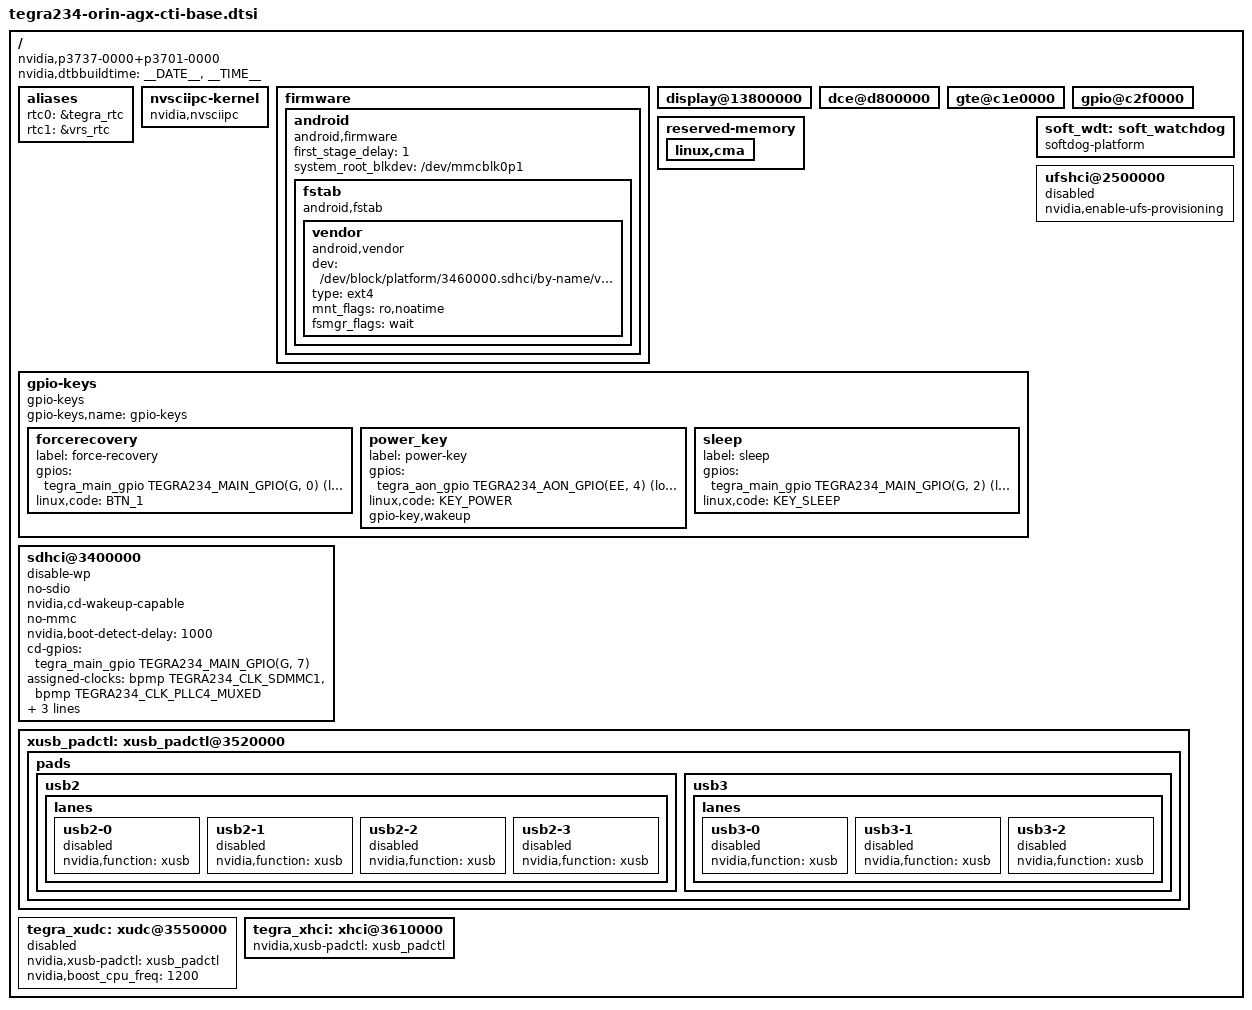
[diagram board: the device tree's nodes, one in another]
/*
 * Top level DTS file for CVM:P3701-0000 and CVB:P3737-0000.
 *
 * Copyright (c) 2021-2022, NVIDIA CORPORATION.  All rights reserved.
 *
 * This program is free software; you can redistribute it and/or modify
 * it under the terms of the GNU General Public License as published by
 * the Free Software Foundation; version 2 of the License.
 *
 * This program is distributed in the hope that it will be useful, but WITHOUT
 * ANY WARRANTY; without even the implied warranty of MERCHANTABILITY or
 * FITNESS FOR A PARTICULAR PURPOSE.  See the GNU General Public License for
 * more details.
 */

/dts-v1/;
#include <dt-bindings/gpio/tegra234-gpio.h>
#include <dt-bindings/input/input.h>
#include <tegra234-soc/mods-simple-bus.dtsi>

#include "../cvm/tegra234-p3701-0000.dtsi"
#include "../tegra234-dcb-p3701-0000-a02-p3737-0000-a01.dtsi"
#include "../tegra234-p3701-0000-prod.dtsi"

#include "cti_common/tegra234-orin-agx-cti-ethernet.dtsi"
#include "cti_common/tegra234-orin-agx-cti-thermal.dtsi"
#include "cti_common/tegra234-orin-agx-cti-cpu.dtsi"
#include "cti_common/tegra234-orin-agx-cti-power-tree.dtsi"

/ {
	nvidia,dtbbuildtime = __DATE__, __TIME__;

	compatible = "nvidia,p3737-0000+p3701-0000", "nvidia,tegra234", "nvidia,tegra23x";
    aliases {
        rtc0 = &tegra_rtc;
        rtc1 = &vrs_rtc;
    };

	nvsciipc-kernel {
		compatible = "nvidia,nvsciipc";
		status = "okay";
	};

	firmware {
		android {
			compatible = "android,firmware";
			first_stage_delay = "1";
			system_root_blkdev = "/dev/mmcblk0p1";
			fstab {
				compatible = "android,fstab";
				vendor {
					compatible = "android,vendor";
					dev = "/dev/block/platform/3460000.sdhci/by-name/vendor";
					type = "ext4";
					mnt_flags = "ro,noatime";
					fsmgr_flags = "wait";
				};
			};
		};
	};
	
	display@13800000 {
		status = "okay";
	};
	dce@d800000 {
		status = "okay";
	};
	gte@c1e0000 {
		status = "okay";
	};
	gpio@c2f0000 {
		/delete-property/ use-timestamp;
	};

	reserved-memory {
		linux,cma {
			status = "okay";
		};
	};
	
	gpio-keys {
		compatible = "gpio-keys";
		gpio-keys,name = "gpio-keys";
		status = "okay";

		forcerecovery {
			label = "force-recovery";
			gpios = <&tegra_main_gpio TEGRA234_MAIN_GPIO(G, 0) GPIO_ACTIVE_LOW>;
			linux,code = <BTN_1>;
		};

		power_key {
			label = "power-key";
			gpios = <&tegra_aon_gpio TEGRA234_AON_GPIO(EE, 4) GPIO_ACTIVE_LOW>;
			linux,code = <KEY_POWER>;
			gpio-key,wakeup;
		};

		sleep {
			label = "sleep";
			gpios = <&tegra_main_gpio TEGRA234_MAIN_GPIO(G, 2) GPIO_ACTIVE_LOW>;
			linux,code = <KEY_SLEEP>;
		};
	};

	soft_wdt:soft_watchdog {
		compatible = "softdog-platform";
		status = "okay";
	};


	ufshci@2500000 {
		nvidia,enable-ufs-provisioning;
		status = "disabled";
	};

	sdhci@3400000 {
		disable-wp;
		no-sdio;
		nvidia,cd-wakeup-capable;
		no-mmc;
		nvidia,boot-detect-delay = <1000>;
		cd-gpios = <&tegra_main_gpio TEGRA234_MAIN_GPIO(G, 7) 0>;
		assigned-clocks = <&bpmp TEGRA234_CLK_SDMMC1>,
				  <&bpmp TEGRA234_CLK_PLLC4_MUXED>;
		assigned-clock-parents = <&bpmp TEGRA234_CLK_PLLC4_MUXED>,
					 <&bpmp TEGRA234_CLK_PLLC4_VCO_DIV2>;
		status = "okay";
	};

	xusb_padctl: xusb_padctl@3520000 {
		status = "okay";
		pads {
			usb2 {
				lanes {
					usb2-0 {
						nvidia,function = "xusb";
						status = "disabled";
					};
					usb2-1 {
						nvidia,function = "xusb";
						status = "disabled";
					};
					usb2-2 {
						nvidia,function = "xusb";
						status = "disabled";
					};
					usb2-3 {
						nvidia,function = "xusb";
						status = "disabled";
					};
				};
			};
			usb3 {
				lanes {
					usb3-0 {
						nvidia,function = "xusb";
						status = "disabled";
					};
					usb3-1 {
						nvidia,function = "xusb";
						status = "disabled";
					};
					usb3-2 {
						nvidia,function = "xusb";
						status = "disabled";
					};
				};
			};
		};
	};

	tegra_xudc: xudc@3550000 {
		status = "disabled";
		nvidia,xusb-padctl = <&xusb_padctl>;
		nvidia,boost_cpu_freq = <1200>;
	};

	tegra_xhci: xhci@3610000 {
		status = "okay";
		nvidia,xusb-padctl = <&xusb_padctl>;
	};
};
